# MKM34Z7 register map
Vendor: Freescale Semiconductor, Inc.; Series: Kinetis_M; File version: 1.6
CPU: CM0PLUS r0p0, little endian, no MPU, no FPU, VTOR, 2 interrupt priority bits
Registers are 8-bit, read-write, reset 0x0 unless marked. A register's access mark holds for its fields unless they carry their own. Offsets are from the block's base; [hi:lo] are bit positions; {n}, {i} and the like mark numbered series.

## XBAR — Crossbar Switch
Base 0x40055000; register names take the prefix XBAR_
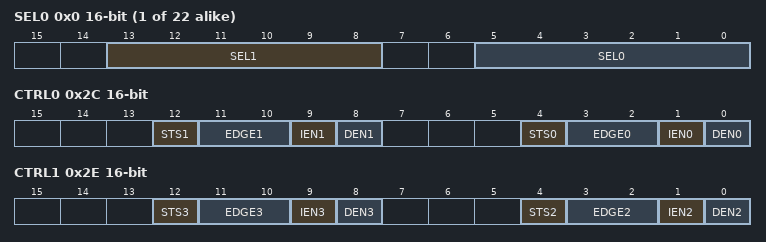
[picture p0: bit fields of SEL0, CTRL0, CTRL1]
{0x0+2i} SEL{i} 16-bit (i=0..21) — Crossbar Select Register {i}
  [13:8] SEL{2i+1}, [5:0] SEL{2i}
0x2C CTRL0 16-bit — Crossbar Control Register 0
  [12] STS1 — Edge detection status for XBAR_OUT1
    0=Active edge not yet detected on XBAR_OUT1; 1=Active edge detected on XBAR_OUT1
  [11:10] EDGE1 — Active edge for edge detection on XBAR_OUT1
    0=STS1 never asserts; 1=STS1 asserts on rising edges of XBAR_OUT1; 2=STS1 asserts on falling edges of XBAR_OUT1; 3=STS1 asserts on rising and falling edges of XBAR_OUT1
  [9] IEN1 — Interrupt Enable for XBAR_OUT1
    0=Interrupt disabled; 1=Interrupt enabled
  [8] DEN1 — DMA Enable for XBAR_OUT1
    0=DMA disabled; 1=DMA enabled
  [4] STS0 — Edge detection status for XBAR_OUT0
    0=Active edge not yet detected on XBAR_OUT0; 1=Active edge detected on XBAR_OUT0
  [3:2] EDGE0 — Active edge for edge detection on XBAR_OUT0
    0=STS0 never asserts; 1=STS0 asserts on rising edges of XBAR_OUT0; 2=STS0 asserts on falling edges of XBAR_OUT0; 3=STS0 asserts on rising and falling edges of XBAR_OUT0
  [1] IEN0 — Interrupt Enable for XBAR_OUT0
    0=Interrupt disabled; 1=Interrupt enabled
  [0] DEN0 — DMA Enable for XBAR_OUT0
    0=DMA disabled; 1=DMA enabled
0x2E CTRL1 16-bit — Crossbar Control Register 1
  [12] STS3 — Edge detection status for XBAR_OUT3
    0=Active edge not yet detected on XBAR_OUT3; 1=Active edge detected on XBAR_OUT3
  [11:10] EDGE3 — Active edge for edge detection on XBAR_OUT3
    0=STS3 never asserts; 1=STS3 asserts on rising edges of XBAR_OUT3; 2=STS3 asserts on falling edges of XBAR_OUT3; 3=STS3 asserts on rising and falling edges of XBAR_OUT3
  [9] IEN3 — Interrupt Enable for XBAR_OUT3
    0=Interrupt disabled; 1=Interrupt enabled
  [8] DEN3 — DMA Enable for XBAR_OUT3
    0=DMA disabled; 1=DMA enabled
  [4] STS2 — Edge detection status for XBAR_OUT2
    0=Active edge not yet detected on XBAR_OUT2; 1=Active edge detected on XBAR_OUT2
  [3:2] EDGE2 — Active edge for edge detection on XBAR_OUT2
    0=STS2 never asserts; 1=STS2 asserts on rising edges of XBAR_OUT2; 2=STS2 asserts on falling edges of XBAR_OUT2; 3=STS2 asserts on rising and falling edges of XBAR_OUT2
  [1] IEN2 — Interrupt Enable for XBAR_OUT2
    0=Interrupt disabled; 1=Interrupt enabled
  [0] DEN2 — DMA Enable for XBAR_OUT2
    0=DMA disabled; 1=DMA enabled

## EWM — External Watchdog Monitor
Base 0x40061000; register names take the prefix EWM_
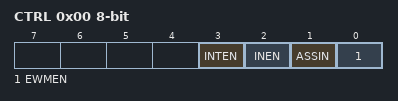
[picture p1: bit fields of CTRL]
0x00 CTRL — Control Register
  [3] INTEN — Interrupt Enable.
  [2] INEN — Input Enable.
  [1] ASSIN — EWM_in's Assertion State Select.
  [0] EWMEN — EWM enable.
0x01 SERV wo — Service Register
  [7:0] SERVICE
0x02 CMPL — Compare Low Register
  [7:0] COMPAREL
0x03 CMPH reset 0xFF — Compare High Register
  [7:0] COMPAREH
0x04 CLKCTRL — Clock Control Register
  [1:0] CLKSEL
0x05 CLKPRESCALER — Clock Prescaler Register
  [7:0] CLK_DIV

## OSC — Oscillator
Base 0x40066000; register names take the prefix OSC_
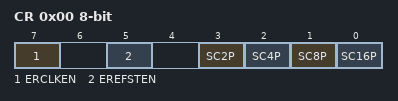
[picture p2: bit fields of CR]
0x00 CR — OSC Control Register
  [7] ERCLKEN — External Reference Enable
    0=External reference clock is inactive; 1=External reference clock is enabled
  [5] EREFSTEN — External Reference Stop Enable
    0=External reference clock is disabled in Stop mode; 1=External reference clock stays enabled in Stop mode if ERCLKEN is set before entering Stop mode
  [3] SC2P — Oscillator 2 pF Capacitor Load Configure
    0=Disable the selection; 1=Add 2 pF capacitor to the oscillator load
  [2] SC4P — Oscillator 4 pF Capacitor Load Configure
    0=Disable the selection; 1=Add 4 pF capacitor to the oscillator load
  [1] SC8P — Oscillator 8 pF Capacitor Load Configure
    0=Disable the selection; 1=Add 8 pF capacitor to the oscillator load
  [0] SC16P — Oscillator 16 pF Capacitor Load Configure
    0=Disable the selection; 1=Add 16 pF capacitor to the oscillator load
